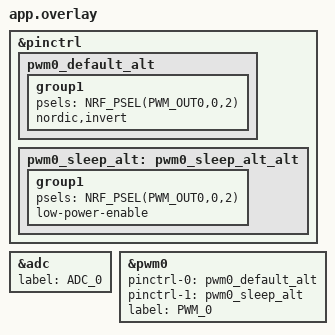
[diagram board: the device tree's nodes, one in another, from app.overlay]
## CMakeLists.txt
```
# SPDX-License-Identifier: Apache-2.0

cmake_minimum_required(VERSION 3.13.1)

find_package(Zephyr REQUIRED HINTS $ENV{ZEPHYR_BASE})
project(microbit_matrix)

target_sources(app PRIVATE src/main.c src/adc.c src/pwm.c)
zephyr_include_directories(${ZEPHYR_BASE}/boards/arm/bbc_microbit_v2)
```

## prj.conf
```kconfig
CONFIG_STDOUT_CONSOLE=y
CONFIG_GPIO=y
CONFIG_ADC=y
CONFIG_PWM=y
CONFIG_PWM_LOG_LEVEL_DBG=y
```

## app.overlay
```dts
/*
 *
 * SPDX-License-Identifier: Apache-2.0
 */
&pinctrl {
    pwm0_default_alt: pwm0_default_alt {
        group1  {
            psels = <NRF_PSEL(PWM_OUT0,0,2)>;
            nordic,invert;
        };
    };
    pwm0_sleep_alt: pwm0_sleep_alt_alt {
        group1  {
            psels = <NRF_PSEL(PWM_OUT0,0,2)>;
            low-power-enable;
        };
    };
};
&adc {
	status = "okay";
    label = "ADC_0";
    
};
&pwm0 {
	status = "okay";
	//ch0-pin = <3>; // P0.3 is labelled RING1 on the microbit. (connected to pin 1 in breakout board)
    pinctrl-0 = <&pwm0_default_alt>;
    pinctrl-1 = <&pwm0_sleep_alt>;
    pinctrl-names = "default", "sleep";

    label="PWM_0";
};
```

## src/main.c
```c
/*
 * SPDX-License-Identifier: Apache-2.0
*/
// Reads an analogue voltage on AIN1 and outputs a PWM signal in proportion to this on GPIO0.2
#include <zephyr/zephyr.h>
#include <zephyr/sys/printk.h>
#include <zephyr/device.h>	
#include <stdio.h>
#include "adc.h"
#include "pwm.h"
void main(void)
{
	int ret;
    ret = adc_begin();	
	if (ret < 0)
	{
		printf("\nError initializing adc.  Error code = %d\n",ret);	
		while(1);
	}
	ret = pwm_begin();	
	if (ret < 0)
	{
		printf("\nError initializing PWM.  Error code = %d\n",ret);	
		while(1);
	}
	 pwm_write((2048* PWM_PERIOD_NS   )/4095);
		k_msleep(100);
	while(1)
	{       
		uint32_t adcvalue = adc_readDigital();
		printf("ADC Digital = %u\n",adcvalue);
		/* The default version of printf does not support floating point numbers so scale up to an integer */
		printf("ADC Voltage (mV) = %d\n",(int)(1000*adc_readVoltage()));
		pwm_write((adcvalue * PWM_PERIOD_NS   )/4095);
		k_msleep(100);
	}
}
```

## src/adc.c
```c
#include <stdint.h>
#include <zephyr/sys/printk.h>
#include <zephyr/device.h>
#include <zephyr/drivers/adc.h>
#include <stdio.h>
#include "adc.h"
/*
 * The internal voltage reference is 0.6V
 * The permissable gains are 1/6, 1/5, 1/4, 1/3, 1/2, 1, 2 and 4
 * If a gain of 1/5 is selected then the ADC range becomes 0 to 3V
 */
static const struct device *adc;
// Will read from analog input on P0.2 which is RING 0 on the microbit v2
#define ADC_PORT_BIT 2
#define ADC_RANGE 3.0
struct adc_channel_cfg channel_cfg = {
		/* gain of 1/5 */
		.gain = ADC_GAIN_1_5,
		/* 0.6V reference */
		.reference = ADC_REF_INTERNAL,
		/* sample and hold time of 3us is the default (0 setting) on the NRF52833 */
		.acquisition_time = ADC_ACQ_TIME_DEFAULT,
		/* Channel 0 */
		.channel_id = 1,
		/* AIN0 is specified by setting input_positive to 0+1 i.e. an offset of 1  */
		/* This is as a result of the way the PSELP and PSELN registers work in the NRF52 series of devices */
		/* see page 375 of the NRF52 product specificatoin version : 4452_021 v1.3 */
		.input_positive = 2,
		/* Using single ended conversions */
        .differential = 0
};
static int16_t channel_0_data;  // This will hold the adc result

struct adc_sequence sequence = {        
		/* This is a bitmask that tells the driver which channels to convert : bit n = 1 for channel n */		
		.channels    = (1 << 1),
		/* Where will the data be stored (could be an array if there are multiple channels to convert */
		.buffer      = &channel_0_data,
		/* buffer size in bytes, not number of samples */
		.buffer_size = sizeof(channel_0_data),
		/* 12 bit resolution */
		.resolution  = 12,
		/* nulls for the rest of the fields */
		.options = NULL,
		.calibrate = 0,
		.oversampling = 0,        
};
int adc_readDigital()
{
	int ret;
	ret = adc_read(adc, &sequence);	
	return channel_0_data;
}
int adc_begin()
{
	int ret;
	// Configure the GPIO's 	
	adc=device_get_binding("ADC_0");
	if (adc == NULL)
	{
		printf("Error acquiring ADC \n");
		return -1;
	}
	ret = adc_channel_setup(adc, &channel_cfg);
	if (ret < 0)
	{
		printf("Error configuring ADC channel 0\n");
		return -2;
	}		
	return 0;
}
double adc_readVoltage()
{
	double returnValue = adc_readDigital();
	returnValue = (returnValue * ADC_RANGE) / 4095.0;
	return returnValue;
}
```

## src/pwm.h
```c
#ifndef __PWM_H
#define __PWM_H
// Set PWM period to 1ms (1 million nano seconds)
#define PWM_PERIOD_NS 1000000
int pwm_begin();
int pwm_write(uint32_t value);
#endif
```
